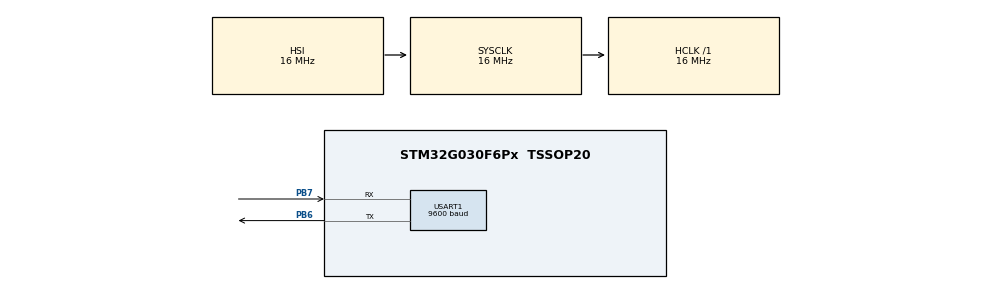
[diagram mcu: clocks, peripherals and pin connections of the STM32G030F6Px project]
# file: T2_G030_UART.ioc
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Mcu.Family=STM32G0
Mcu.Name=STM32G030F6Px
Mcu.Package=TSSOP20
PA14-BOOT0__PA15.StandardMode=true
PB0__PB1__PB2__PA8.StandardMode=true
PB3__PB4__PB5__PB6.StandardMode=true
PB6.Mode=Asynchronous
PB6.Signal=USART1_TX
PB7.Mode=Asynchronous
PB7.Signal=USART1_RX
PB7__PB8.StandardMode=true
PC14-OSC32_IN\ (PC14)__PB9.StandardMode=true
ProjectManager.HeapSize=0x200
ProjectManager.StackSize=0x400
ProjectManager.TargetToolchain=STM32CubeIDE
RCC.AHBFreq_Value=16000000
RCC.CortexFreq_Value=16000000
RCC.EXTERNAL_CLOCK_VALUE=12288000
RCC.HCLKFreq_Value=16000000
RCC.HSE_VALUE=8000000
RCC.HSI_VALUE=16000000
RCC.LSE_VALUE=32768
RCC.SYSCLKFreq_VALUE=16000000
RCC.VCOOutputFreq_Value=128000000
USART1.BaudRate=9600
USART1.VirtualMode-Asynchronous=VM_ASYNC
board=custom

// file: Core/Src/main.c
/* USER CODE BEGIN Header */
/**
  ******************************************************************************
  * @file           : main.c
  * @brief          : Main program body
  ******************************************************************************
  * @attention
  *
  * Copyright (c) 2024 STMicroelectronics.
  * All rights reserved.
  *
  * This software is licensed under terms that can be found in the LICENSE file
  * in the root directory of this software component.
  * If no LICENSE file comes with this software, it is provided AS-IS.
  *
  ******************************************************************************
  */
/* USER CODE END Header */
#include "main.h"

/* USER CODE BEGIN Includes */
#include "string.h"
#include "result_format.h"
/* USER CODE END Includes */

UART_HandleTypeDef huart1;

void SystemClock_Config(void);
static void MX_GPIO_Init(void);
static void MX_USART1_UART_Init(void);

/* USER CODE BEGIN 0 */
UART_HandleTypeDef huart1;

/* USER CODE END 0 */

int main(void)
{

  /* MCU Configuration--------------------------------------------------------*/

  /* Reset of all peripherals, Initializes the Flash interface and the Systick. */
  HAL_Init();

  /* Configure the system clock */
  SystemClock_Config();

  /* Initialize all configured peripherals */
  MX_GPIO_Init();
  MX_USART1_UART_Init();
  /* USER CODE BEGIN 2 */

//  uint8_t model[]="PI1-05 P\n";
//  uint8_t company[]="-01-001 Ver.1.0\n";
//  Vaccum_test_result_title(model,company);
//  uint8_t company_name[] = "\n";
//  uint8_t location[]="\n";
//  uint8_t test_date[]="23/02/2024\n";
//  uint8_t test_start_time[] = "12:22:20\n";
//  uint8_t test_end_time []= "27:33:02\n";
//  uint8_t user_name[]="\n";
//
//  Vaccum_test_result_report(company_name,location,test_date,test_start_time,test_end_time,user_name);
//
//  uint8_t prod_name[]="\n";
//  uint8_t prod_no[]="\n";
//  uint8_t batch_no[]="\n";
//  uint8_t batch_size[]="\n";
//  uint8_t sample_qty[]="\n";
//  uint8_t package_type[] ="\n";
//  uint8_t tolerance[] ="\n";
//
//  User_prod_details(prod_name,prod_no,batch_no,batch_size,sample_qty,package_type,tolerance);
//
//  uint8_t set_vaccum[]="060 mm/Hg\n";
//  uint8_t act_vaccum[]="060 mm/Hg\n";
//  uint8_t set_pressure[]="0.0799 bar\n";
//  uint8_t act_pressure[]="0.0799 bar\n";
////  uint8_t test_duration[]="0005 sec\n";
//
//
//  Test_settings(set_vaccum,act_vaccum,set_pressure,act_pressure);

//  uint8_t test_duration[] ="\n";
//  uint8_t test_sample_no[] ="\n";
//  uint8_t weight_before_test[] ="\n";
//  uint8_t weight_after_test[] ="\n";
//  uint8_t difference[]="\n";
//  uint8_t test_result[]="\n";

//  Test_result(test_duration,test_sample_no,weight_before_test,weight_after_test,difference,test_result);

//  uint8_t performed_by[]="\n";
//  uint8_t test_status[]="\n";
//  uint8_t verified_by[]="\n";
//  uint8_t sign[]="\n";

//  Test_status(test_status,performed_by,verified_by,sign);

// uint8_t date[]="23/02/2024 ";
// uint8_t time[]="19:22:33\n";
// Printred_on(date,time);

//Validation function calling...

  uint8_t model[]="PI1-05 P\n";
  uint8_t company[]="-01-001 Ver.1.0\n";

  Vaccum_test_result_title(model,company);

  uint8_t company_name[]="\n";
  uint8_t location[]="\n";
  uint8_t test_date[]="\n";
  uint8_t test_start_time[]="\n";
  uint8_t test_end_time[]="\n";

  Validation_report_start(company_name,location,test_date,test_start_time,test_end_time);

  uint8_t prod_name[]="\n";
  uint8_t prod_no[]="\n";

  Validation_report_product_details(prod_name,prod_no);

  uint8_t test_number[]="\n";
  uint8_t input[]="\n";
  uint8_t maintained[]="\n";
  uint8_t meter[]="\n";
  uint8_t difference[]="\n";
  uint8_t results[]="\n";

  Validation_report_results(test_number,input,maintained,meter,difference,results);
  uint8_t performed_by[]="\n";
  uint8_t verified_by[]="\n";
  uint8_t sign[]="\n";
  Validation_report_end(performed_by,verified_by,sign);

  uint8_t date[]="23/02/2024 ";
  uint8_t time[]="19:22:33\n";
  Printred_on(date,time);

  /* USER CODE END 2 */

  /* Infinite loop */
  /* USER CODE BEGIN WHILE */

//  uint8_t data2[] = "Package Integrity tester\n";
  while (1)
  {
//	  HAL_UART_Transmit(&huart1,&data1, strlen(data1), HAL_MAX_DELAY);
//	  HAL_UART_Transmit(&huart1, &data, strlen(data), HAL_MAX_DELAY);
//	  HAL_Delay(1000);
//	  HAL_UART_Transmit(&huart1, &data2, strlen(data2), HAL_MAX_DELAY);

    /* USER CODE END WHILE */

  }
}

void SystemClock_Config(void)
{
  RCC_OscInitTypeDef RCC_OscInitStruct = {0};
  RCC_ClkInitTypeDef RCC_ClkInitStruct = {0};

  /** Configure the main internal regulator output voltage
  */
  HAL_PWREx_ControlVoltageScaling(PWR_REGULATOR_VOLTAGE_SCALE1);

  /** Initializes the RCC Oscillators according to the specified parameters
  * in the RCC_OscInitTypeDef structure.
  */
  RCC_OscInitStruct.OscillatorType = RCC_OSCILLATORTYPE_HSI;
  RCC_OscInitStruct.HSIState = RCC_HSI_ON;
  RCC_OscInitStruct.HSIDiv = RCC_HSI_DIV1;
  RCC_OscInitStruct.HSICalibrationValue = RCC_HSICALIBRATION_DEFAULT;
  RCC_OscInitStruct.PLL.PLLState = RCC_PLL_NONE;
  if (HAL_RCC_OscConfig(&RCC_OscInitStruct) != HAL_OK)
  {
    Error_Handler();
  }

  /** Initializes the CPU, AHB and APB buses clocks
  */
  RCC_ClkInitStruct.ClockType = RCC_CLOCKTYPE_HCLK|RCC_CLOCKTYPE_SYSCLK
                              |RCC_CLOCKTYPE_PCLK1;
  RCC_ClkInitStruct.SYSCLKSource = RCC_SYSCLKSOURCE_HSI;
  RCC_ClkInitStruct.AHBCLKDivider = RCC_SYSCLK_DIV1;
  RCC_ClkInitStruct.APB1CLKDivider = RCC_HCLK_DIV1;

  if (HAL_RCC_ClockConfig(&RCC_ClkInitStruct, FLASH_LATENCY_0) != HAL_OK)
  {
    Error_Handler();
  }
}

static void MX_USART1_UART_Init(void)
{

  huart1.Instance = USART1;
  huart1.Init.BaudRate = 9600;
  huart1.Init.WordLength = UART_WORDLENGTH_8B;
  huart1.Init.StopBits = UART_STOPBITS_1;
  huart1.Init.Parity = UART_PARITY_NONE;
  huart1.Init.Mode = UART_MODE_TX_RX;
  huart1.Init.HwFlowCtl = UART_HWCONTROL_NONE;
  huart1.Init.OverSampling = UART_OVERSAMPLING_16;
  huart1.Init.OneBitSampling = UART_ONE_BIT_SAMPLE_DISABLE;
  huart1.Init.ClockPrescaler = UART_PRESCALER_DIV1;
  huart1.AdvancedInit.AdvFeatureInit = UART_ADVFEATURE_NO_INIT;
  if (HAL_UART_Init(&huart1) != HAL_OK)
  {
    Error_Handler();
  }
  if (HAL_UARTEx_SetTxFifoThreshold(&huart1, UART_TXFIFO_THRESHOLD_1_8) != HAL_OK)
  {
    Error_Handler();
  }
  if (HAL_UARTEx_SetRxFifoThreshold(&huart1, UART_RXFIFO_THRESHOLD_1_8) != HAL_OK)
  {
    Error_Handler();
  }
  if (HAL_UARTEx_DisableFifoMode(&huart1) != HAL_OK)
  {
    Error_Handler();
  }

}

static void MX_GPIO_Init(void)
{

  /* GPIO Ports Clock Enable */
  __HAL_RCC_GPIOB_CLK_ENABLE();

}

void Error_Handler(void)
{
  __disable_irq();
  while (1)
  {
  }
}
